# STM32WL5X_CM0P register map
File version: 2.1
CPU: CM0 r0p1, little endian, MPU, no FPU, 4 interrupt priority bits
Registers are 32-bit, read-write, reset 0x0 unless marked. A register's access mark holds for its fields unless they carry their own. Offsets are from the block's base; [hi:lo] are bit positions; {n}, {i} and the like mark numbered series; 'fields as' and 'values as' point back to an identical list.

## HSEM — Hardware semaphore
Base 0x58001400
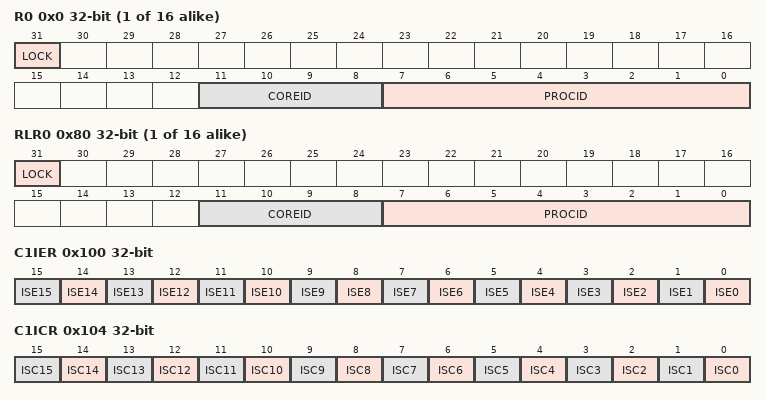
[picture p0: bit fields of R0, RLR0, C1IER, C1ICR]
{0x0+4i} R{i} (i=0..15) — HSEM register HSEM_R{i}
  [31] LOCK — Lock indication
    on read: 0=Free (Semaphore is free); 1=Locked (Semaphore is locked) | on write: 0=Free semaphore; 1=TryLock (Try to lock semaphore)
  [11:8] COREID
  [7:0] PROCID — Semaphore ProcessID
{0x80+4i} RLR{i} (i=0..15) ro — Semaphore {i} read lock register
  [31] LOCK — Lock indication
    0=Free (Semaphore is free); 1=Locked (Semaphore is locked)
  [11:8] COREID
  [7:0] PROCID — Semaphore ProcessID
0x100 C1IER — HSEM Interrupt enable register
  [n] ISE{n} (n=0..15) — Interrupt semaphore {n} enable bit
    0=Disabled (Interrupt generation disabled); 1=Enabled (Interrupt generation enabled)
0x104 C1ICR — HSEM Interrupt clear register
  [n] ISC{n} (n=0..15) — Interrupt semaphore {n} clear bit
    on read: 0=NoEffect (Always reads 0) | on write: 0=NoEffect (Interrupt semaphore x status ISFx and masked status MISFx not affected); 1=Clear (Interrupt semaphore x status ISFx and masked status MISFx cleared)
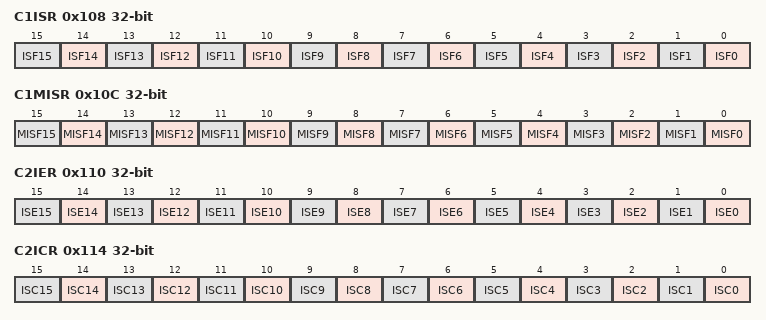
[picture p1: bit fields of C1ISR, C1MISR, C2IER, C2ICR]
0x108 C1ISR ro — HSEM Interrupt status register
  [n] ISF{n} (n=0..15) — Interrupt semaphore {n} status bit before enable (mask)
    0=NotPending (No interrupt pending); 1=Pending (Interrupt pending)
0x10C C1MISR ro — HSEM Masked interrupt status register
  [n] MISF{n} (n=0..15) — Masked interrupt semaphore {n} status bit after enable (mask)
    0=NotPending (No interrupt pending after masking); 1=Pending (Interrupt pending after masking)
0x110 C2IER — HSEM Interrupt enable register
  fields as C1IER
0x114 C2ICR — HSEM Interrupt clear register
  fields as C1ICR
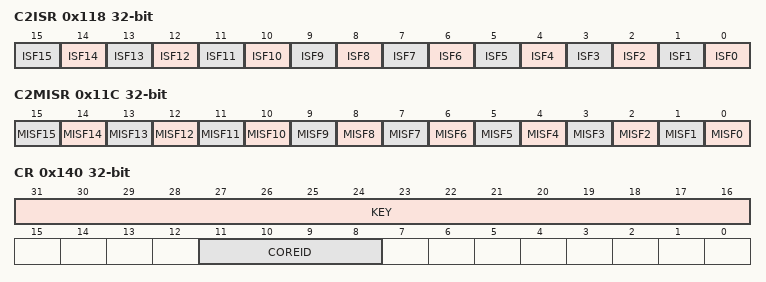
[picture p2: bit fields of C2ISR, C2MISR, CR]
0x118 C2ISR ro — HSEM Interrupt status register
  fields as C1ISR
0x11C C2MISR ro — HSEM Masked interrupt status register
  fields as C1MISR
0x140 CR wo — HSEM Clear register
  [31:16] KEY — Semaphore clear Key
  [11:8] COREID
0x144 KEYR — HSEM Interrupt clear register
  [31:16] KEY — Semaphore Clear Key

## IPCC — Inter Processor communication controller
Base 0x58000C00
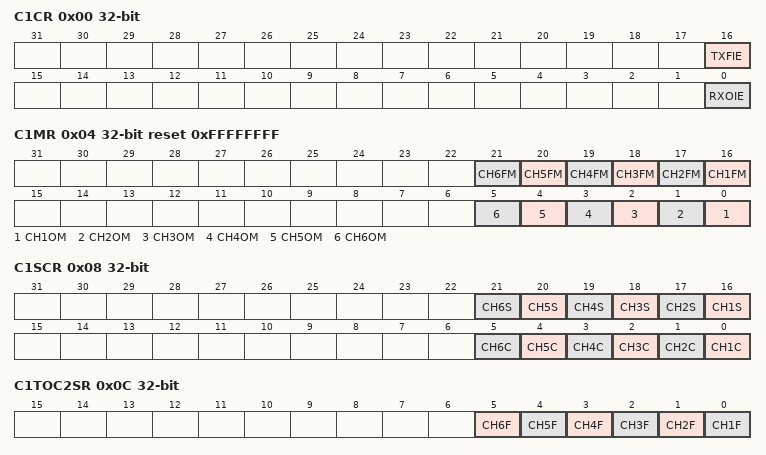
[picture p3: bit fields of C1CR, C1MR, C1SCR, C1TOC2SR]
0x00 C1CR — IPCC Processor 1 control register
  [16] TXFIE
    0=Disabled (Processor TX free interrupt disabled); 1=Enabled (Enable an unmasked processor transmit channel free to generate a TX free interrupt)
  [0] RXOIE
    0=Disabled (Processor RX occupied interrupt disabled); 1=Enabled (Enable an unmasked processor receive channel occupied to generate an RX occupied interrupt)
0x04 C1MR reset 0xFFFFFFFF — IPCC Processor 1 mask register
  [n+15] CH{n}FM (n=1..6)
    0=Unmasked (Transmit channel n free interrupt not masked); 1=Masked (Transmit channel n free interrupt masked)
  [n-1] CH{n}OM (n=1..6)
    0=Unmasked (Receive channel n occupied interrupt not masked); 1=Masked (Receive channel n occupied interrupt masked)
0x08 C1SCR — Reading this register will always return 0x0000 0000.
  [n+15] CH{n}S (n=1..6)
    0=NoAction; 1=Set (Processor transmit channel n status bit set)
  [n-1] CH{n}C (n=1..6)
    0=NoAction; 1=Clear (Processor receive channel n status bit clear)
0x0C C1TOC2SR ro — IPCC processor 1 to processor 2 status register
  [5] CH6F
  [n-1] CH{n}F (n=1..5)
    0=Free (Channel free, data can be written by the sending processor. Generates a channel TX free interrupt to the current processor, when unmasked); 1=Occupied (Channel occupied, data can be read by the receiving processor. Generates a channel RX occupied interrupt to the other processor, when unmasked)
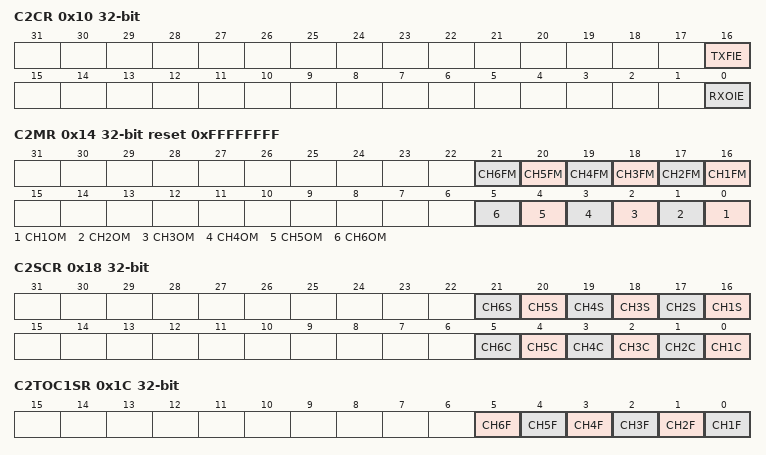
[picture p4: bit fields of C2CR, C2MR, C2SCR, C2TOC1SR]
0x10 C2CR — IPCC Processor 2 control register
  fields as C1CR
0x14 C2MR reset 0xFFFFFFFF — IPCC Processor 2 mask register
  fields as C1MR
0x18 C2SCR — Reading this register will always return 0x0000 0000.
  fields as C1SCR
0x1C C2TOC1SR ro — IPCC processor 2 to processor 1 status register
  fields as C1TOC2SR
0x3F0 HWCFGR ro reset 0x6 — IPCC Hardware configuration register
  [7:0] CHANNELS
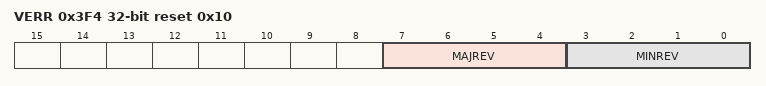
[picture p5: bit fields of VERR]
0x3F4 VERR ro reset 0x10 — IPCC IP Version register
  [7:4] MAJREV, [3:0] MINREV
0x3F8 IPIDR ro reset 0x100071 — IPCC IP Identification register
  [31:0] ID
0x3FC SIDR ro reset 0xA3C5DD01 — IPCC Size ID register
  [31:0] SID
